# ESP32C5_PLATFORM register map
Vendor: Espressif; Series: ESP32-C5; File version: 1
ESP32-C5 platform registers the host reads through the chip's JTAG, never firmware: no PAC is generated from this model. ESP-HAL owns these blocks at runtime.
Registers are 32-bit, read-only, reset 0x0 unless marked. A register's access mark holds for its fields unless they carry their own. Offsets are from the block's base; lines under a group give offsets from that group; [hi:lo] are bit positions; {n}, {i} and the like mark numbered series; 'fields as' and 'values as' point back to an identical list; <NAME> marks a mode.

## Memory map
0x600B0400 LP_CLKRST_RESET_CAUSE — Low-power clock/reset registers: the reset cause of the HP core. Firmware reads it after boot; the host reads it through JTAG after a power cycle.

## LP_CLKRST_RESET_CAUSE — Low-power clock/reset registers: the reset cause of the HP core. Firmware reads it after boot; the host reads it through JTAG after a power cycle.
Base 0x600B0400
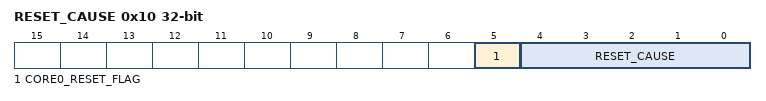
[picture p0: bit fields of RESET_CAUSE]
0x10 RESET_CAUSE — Why the HP core last left reset. It holds until the next reset, so a host reads it through JTAG after the core returned.
  [5] CORE0_RESET_FLAG — Set when the HP core left reset.
  [4:0] RESET_CAUSE — The reset cause code: one is a power-on reset; others are system, watchdog, brown-out, USB Serial/JTAG and JTAG resets.

## Licence text in the file
MIT OR Apache-2.0
